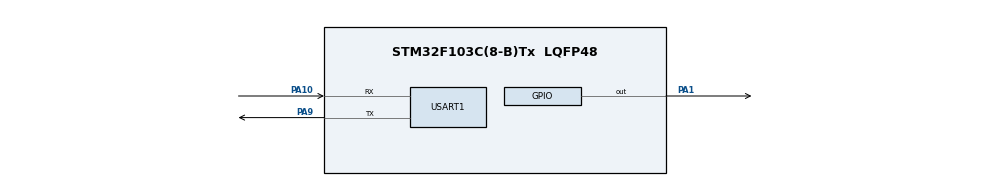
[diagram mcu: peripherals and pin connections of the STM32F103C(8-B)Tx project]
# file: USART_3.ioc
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Mcu.Family=STM32F1
Mcu.Name=STM32F103C(8-B)Tx
Mcu.Package=LQFP48
NVIC.PriorityGroup=NVIC_PRIORITYGROUP_4
NVIC.USART1_IRQn=true\:0\:0\:false\:false\:true\:true\:true\:true
PA1.Signal=GPIO_Output
PA10.Mode=Asynchronous
PA10.Signal=USART1_RX
PA13.Mode=JTAG_5_pins
PA13.Signal=SYS_JTMS-SWDIO
PA14.Mode=JTAG_5_pins
PA14.Signal=SYS_JTCK-SWCLK
PA15.Mode=JTAG_5_pins
PA15.Signal=SYS_JTDI
PA9.Mode=Asynchronous
PA9.Signal=USART1_TX
PB3.Mode=JTAG_5_pins
PB3.Signal=SYS_JTDO-TRACESWO
PB4.Mode=JTAG_5_pins
PB4.Signal=SYS_NJTRST
ProjectManager.HeapSize=0x200
ProjectManager.StackSize=0x400
ProjectManager.TargetToolchain=MDK-ARM V5.32
RCC.APB1Freq_Value=8000000
RCC.APB2Freq_Value=8000000
USART1.VirtualMode=VM_ASYNC
board=custom

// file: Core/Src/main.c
/* USER CODE BEGIN Header */
/**
  ******************************************************************************
  * @file           : main.c
  * @brief          : Main program body
  ******************************************************************************
  * @attention
  *
  * Copyright (c) 2023 STMicroelectronics.
  * All rights reserved.
  *
  * This software is licensed under terms that can be found in the LICENSE file
  * in the root directory of this software component.
  * If no LICENSE file comes with this software, it is provided AS-IS.
  *
  ******************************************************************************
  */
/* USER CODE END Header */
#include "main.h"
#include "usart.h"
#include "gpio.h"

/* USER CODE BEGIN Includes */
#include <stdio.h>
/* USER CODE END Includes */

/* USER CODE BEGIN PV */
uint8_t RxBuffer[4];  // Receive buffer
uint8_t RxFlag = 0;   // Receive completion flag: 0 not completed, 1 completed
uint8_t ErrFlag = 0;  // Command error flag: 0 correct, 1 head and tail error, 2 device code erroe, 3 function code error
/* USER CODE END PV */

void SystemClock_Config(void);

int main(void)
{

  /* MCU Configuration--------------------------------------------------------*/

  /* Reset of all peripherals, Initializes the Flash interface and the Systick. */
  HAL_Init();

  /* Configure the system clock */
  SystemClock_Config();

  /* Initialize all configured peripherals */
  MX_GPIO_Init();
  MX_USART1_UART_Init();
  /* USER CODE BEGIN 2 */
  printf("*****  Communication Frame  *****\n");
  printf("Please enter instruction:\n");
  printf("Head->0xaa, Device->0x01, Operation->0x00/0x10, Tail->0x55\n");
  HAL_UART_Receive_IT(&huart1, (uint8_t*)RxBuffer, 4);
  /* USER CODE END 2 */

  /* Infinite loop */
  while (1)
  {

    /* USER CODE BEGIN 3 */

    // Determine if reception is complete
    if (RxFlag == 1)
    {
      RxFlag = 0;    // Clear flag bit

      // Frame format analysis
      printf("head = RxBuffer[0] = %x\n", RxBuffer[0]);
      printf("tail = RxBuffer[3] = %x\n", RxBuffer[3]);
      printf("device = RxBuffer[1] = %x\n", RxBuffer[1]);
      printf("function = RxBuffer[2] = %x\n", RxBuffer[2]);
      if (RxBuffer[0] == 0xaa && RxBuffer[3] == 0x55)  // Determining the head and tail of a frame
      {
        if (RxBuffer[1] == 0x01)          // Determine the device code
        {
          if (RxBuffer[2] == 0x00)        // Determine the function code
          {
            HAL_GPIO_WritePin(GPIOA, GPIO_PIN_1, GPIO_PIN_RESET);
            printf("LED1 is close!\n");
          }
          else if (RxBuffer[2] == 0x01)   // Determine the function code
          {
            HAL_GPIO_WritePin(GPIOA, GPIO_PIN_1, GPIO_PIN_SET);
            printf("LED1 is open!\n");
          }
          else              // Function code error
          {
            ErrFlag = 3;
          }
        }
        else                // Device code error
        {
          ErrFlag = 2;
        }
      }
      else                  // Head and tail error
      {
        ErrFlag = 1;
      }
      switch (ErrFlag)
      {
        case 1:
          printf("Head and tail error! Please send again!\n");
          break;
        case 2:
          printf("Device code error! Please send again!\n");
          break;
        case 3:
          printf("Function code error! Please send again!\n");
          break;
        default:
          break;
      }
      // Clear the flag bits and buffers in preparation for the next reception
      ErrFlag = 0;
      RxBuffer[0] = 0;
      RxBuffer[1] = 0;
      RxBuffer[2] = 0;
      RxBuffer[3] = 0;
    }
  }
  /* USER CODE END 3 */
}

void SystemClock_Config(void)
{
  RCC_OscInitTypeDef RCC_OscInitStruct = {0};
  RCC_ClkInitTypeDef RCC_ClkInitStruct = {0};

  /** Initializes the RCC Oscillators according to the specified parameters
  * in the RCC_OscInitTypeDef structure.
  */
  RCC_OscInitStruct.OscillatorType = RCC_OSCILLATORTYPE_HSI;
  RCC_OscInitStruct.HSIState = RCC_HSI_ON;
  RCC_OscInitStruct.HSICalibrationValue = RCC_HSICALIBRATION_DEFAULT;
  RCC_OscInitStruct.PLL.PLLState = RCC_PLL_NONE;
  if (HAL_RCC_OscConfig(&RCC_OscInitStruct) != HAL_OK)
  {
    Error_Handler();
  }

  /** Initializes the CPU, AHB and APB buses clocks
  */
  RCC_ClkInitStruct.ClockType = RCC_CLOCKTYPE_HCLK|RCC_CLOCKTYPE_SYSCLK
                              |RCC_CLOCKTYPE_PCLK1|RCC_CLOCKTYPE_PCLK2;
  RCC_ClkInitStruct.SYSCLKSource = RCC_SYSCLKSOURCE_HSI;
  RCC_ClkInitStruct.AHBCLKDivider = RCC_SYSCLK_DIV1;
  RCC_ClkInitStruct.APB1CLKDivider = RCC_HCLK_DIV1;
  RCC_ClkInitStruct.APB2CLKDivider = RCC_HCLK_DIV1;

  if (HAL_RCC_ClockConfig(&RCC_ClkInitStruct, FLASH_LATENCY_0) != HAL_OK)
  {
    Error_Handler();
  }
}

/* USER CODE BEGIN 4 */
int fputc (int ch, FILE *f)
{
    HAL_UART_Transmit(&huart1, (uint8_t *)&ch, 1, HAL_MAX_DELAY);
    return ch;
}

int fgetc(FILE *f)
{
    uint8_t ch = 0;
    HAL_UART_Receive(&huart1, (uint8_t *)&ch, 1, HAL_MAX_DELAY);
    return ch;
}

void HAL_UART_RxCpltCallback(UART_HandleTypeDef *huart)
{
  if (huart->Instance == USART1)
  {
    RxFlag = 1;
    HAL_UART_Receive_IT(&huart1 , (uint8_t*)RxBuffer, 4);
  }
}
/* USER CODE END 4 */

void Error_Handler(void)
{
  __disable_irq();
  while (1)
  {
  }
}
